# PIC32MX330F064L register map
Vendor: Microchip
Registers are 32-bit, read-write, reset 0x0 unless marked. A register's access mark holds for its fields unless they carry their own. Addresses are absolute, and some are shared; only a register's first bit layout is shown; [hi:lo] are bit positions; {n}, {i} and the like mark numbered series.

## ADC10
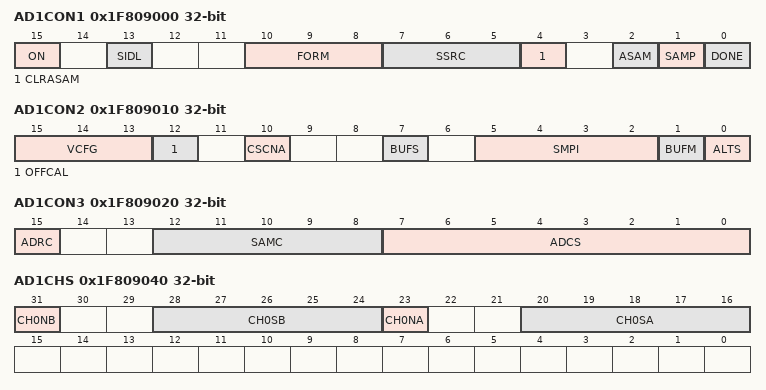
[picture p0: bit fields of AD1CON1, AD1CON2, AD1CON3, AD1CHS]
0x1F809000 AD1CON1
  [15] ON
  [13] SIDL
  [10:8] FORM
  [7:5] SSRC
  [4] CLRASAM
  [2] ASAM
  [1] SAMP
  [0] DONE — (can only be cleared)
0x1F809010 AD1CON2
  [15:13] VCFG, [12] OFFCAL, [10] CSCNA, [7] BUFS ro, [5:2] SMPI, [1] BUFM, [0] ALTS
0x1F809020 AD1CON3
  [15] ADRC, [12:8] SAMC, [7:0] ADCS
0x1F809040 AD1CHS
  [31] CH0NB, [28:24] CH0SB, [23] CH0NA, [20:16] CH0SA
0x1F809050 AD1CSSL
  [30:0] CSSL
{0x1F809070+0x10*i} ADC1BUF{i} ro (i=0..9)
0x1F809110 ADC1BUFA ro
0x1F809120 ADC1BUFB ro
0x1F809130 ADC1BUFC ro
0x1F809140 ADC1BUFD ro
0x1F809150 ADC1BUFE ro
0x1F809160 ADC1BUFF ro

## CVR
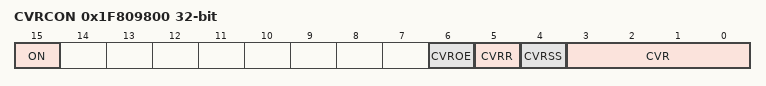
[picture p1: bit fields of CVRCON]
0x1F809800 CVRCON
  [15] ON, [6] CVROE, [5] CVRR, [4] CVRSS, [3:0] CVR

## CMP1
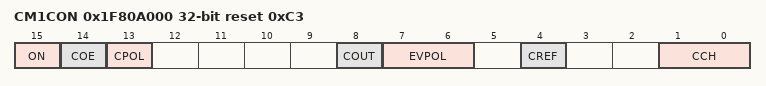
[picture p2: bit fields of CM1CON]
0x1F80A000 CM1CON reset 0xC3
  [15] ON, [14] COE, [13] CPOL, [8] COUT, [7:6] EVPOL, [4] CREF, [1:0] CCH

## CMP2
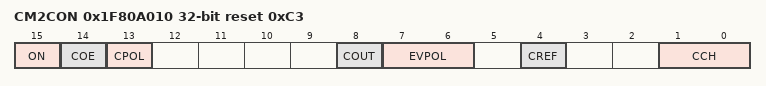
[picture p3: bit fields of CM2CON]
0x1F80A010 CM2CON reset 0xC3
  [15] ON, [14] COE, [13] CPOL, [8] COUT, [7:6] EVPOL, [4] CREF, [1:0] CCH

## cmp_control_pb
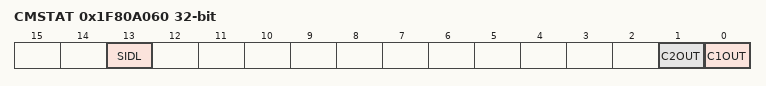
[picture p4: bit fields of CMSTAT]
0x1F80A060 CMSTAT
  [13] SIDL, [1] C2OUT ro, [0] C1OUT ro

## CTMU
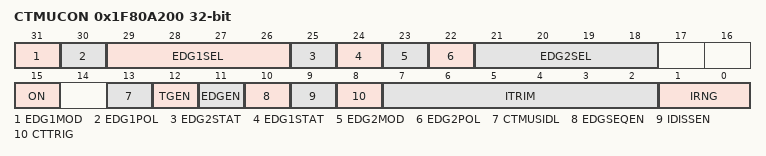
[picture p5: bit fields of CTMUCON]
0x1F80A200 CTMUCON
  [31] EDG1MOD, [30] EDG1POL, [29:26] EDG1SEL, [25] EDG2STAT, [24] EDG1STAT, [23] EDG2MOD, [22] EDG2POL, [21:18] EDG2SEL, [15] ON, [13] CTMUSIDL, [12] TGEN, [11] EDGEN, [10] EDGSEQEN, [9] IDISSEN, [8] CTTRIG, [7:2] ITRIM, [1:0] IRNG

## INT
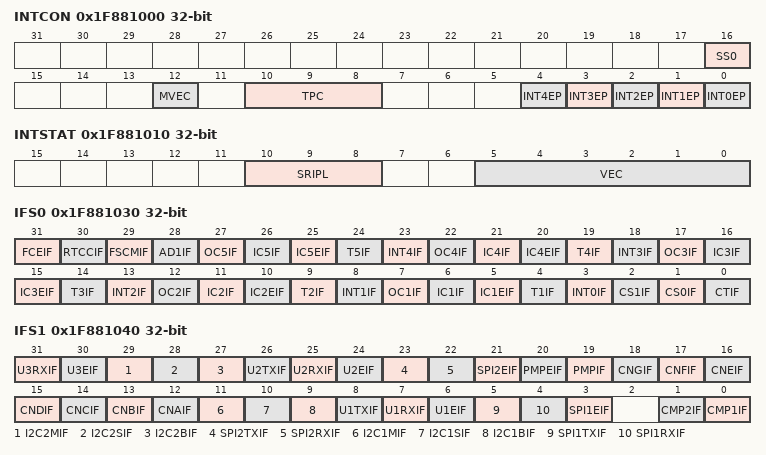
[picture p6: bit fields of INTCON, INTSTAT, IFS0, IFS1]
0x1F881000 INTCON
  [16] SS0, [12] MVEC, [10:8] TPC, [n] INT{n}EP (n=0..4)
0x1F881010 INTSTAT
  [10:8] SRIPL, [5:0] VEC
0x1F881020 IPTMR
0x1F881030 IFS0 reset not defined — (power-on value 00000x0000x0000x0000000000000000)
  [31] FCEIF, [30] RTCCIF, [29] FSCMIF, [28] AD1IF, [5n+2] OC{n}IF (n=1..5), [5n+1] IC{n}IF (n=1..5), [5n] IC{n}EIF (n=1..5), [5n-1] T{n}IF (n=1..5), [5n+3] INT{n}IF (n=0..4), [2] CS1IF, [1] CS0IF, [0] CTIF
0x1F881040 IFS1 reset not defined — (power-on value xxxxxx00xxxx00000000000000000-00)
  [31] U3RXIF, [30] U3EIF, [29] I2C2MIF, [28] I2C2SIF, [27] I2C2BIF, [26] U2TXIF, [25] U2RXIF, [24] U2EIF, [23] SPI2TXIF, [22] SPI2RXIF, [21] SPI2EIF, [20] PMPEIF, [19] PMPIF, [18] CNGIF, [17] CNFIF, [16] CNEIF, [15] CNDIF, [14] CNCIF, [13] CNBIF, [12] CNAIF, [11] I2C1MIF, [10] I2C1SIF, [9] I2C1BIF, [8] U1TXIF, [7] U1RXIF, [6] U1EIF, [5] SPI1TXIF, [4] SPI1RXIF, [3] SPI1EIF, [1] CMP2IF, [0] CMP1IF
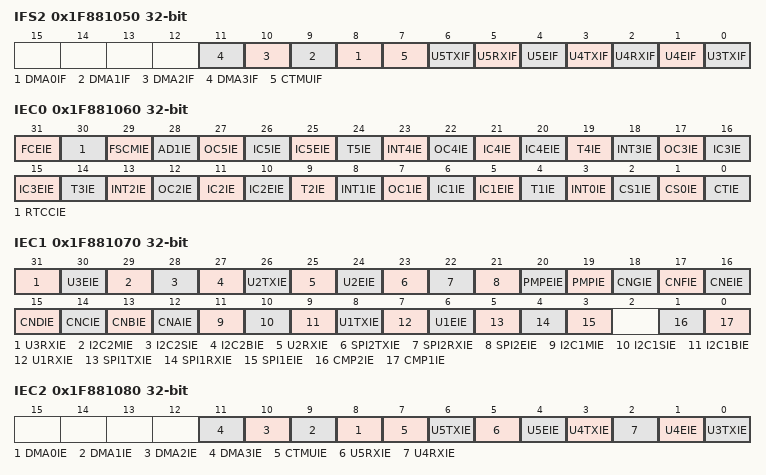
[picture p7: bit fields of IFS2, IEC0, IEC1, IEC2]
0x1F881050 IFS2 reset not defined — (power-on value x-------------------xxxxxxxxxxxx)
  [n+8] DMA{n}IF (n=0..3), [7] CTMUIF, [6] U5TXIF, [5] U5RXIF, [4] U5EIF, [3] U4TXIF, [2] U4RXIF, [1] U4EIF, [0] U3TXIF
0x1F881060 IEC0 reset not defined — (power-on value 00000x0000x0000x0000000000000000)
  [31] FCEIE, [30] RTCCIE, [29] FSCMIE, [28] AD1IE, [5n+2] OC{n}IE (n=1..5), [5n+1] IC{n}IE (n=1..5), [5n] IC{n}EIE (n=1..5), [5n-1] T{n}IE (n=1..5), [5n+3] INT{n}IE (n=0..4), [2] CS1IE, [1] CS0IE, [0] CTIE
0x1F881070 IEC1 reset not defined — (power-on value xxxxxx-0xxxx-0000000000000000-00)
  [31] U3RXIE, [30] U3EIE, [29] I2C2MIE, [28] I2C2SIE, [27] I2C2BIE, [26] U2TXIE, [25] U2RXIE, [24] U2EIE, [23] SPI2TXIE, [22] SPI2RXIE, [21] SPI2EIE, [20] PMPEIE, [19] PMPIE, [18] CNGIE, [17] CNFIE, [16] CNEIE, [15] CNDIE, [14] CNCIE, [13] CNBIE, [12] CNAIE, [11] I2C1MIE, [10] I2C1SIE, [9] I2C1BIE, [8] U1TXIE, [7] U1RXIE, [6] U1EIE, [5] SPI1TXIE, [4] SPI1RXIE, [3] SPI1EIE, [1] CMP2IE, [0] CMP1IE
0x1F881080 IEC2 reset not defined — (power-on value --------------------xxxxxxxxxxxx)
  [n+8] DMA{n}IE (n=0..3), [7] CTMUIE, [6] U5TXIE, [5] U5RXIE, [4] U5EIE, [3] U4TXIE, [2] U4RXIE, [1] U4EIE, [0] U3TXIE
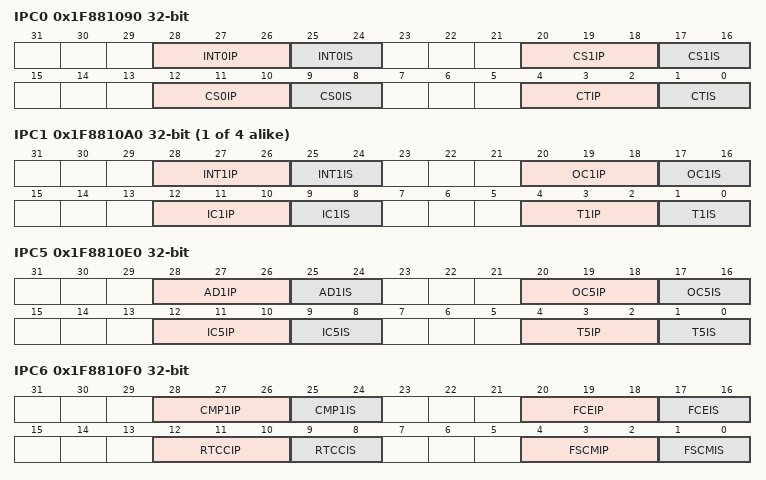
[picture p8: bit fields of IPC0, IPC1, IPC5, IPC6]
0x1F881090 IPC0
  [28:26] INT0IP, [25:24] INT0IS, [20:18] CS1IP, [17:16] CS1IS, [12:10] CS0IP, [9:8] CS0IS, [4:2] CTIP, [1:0] CTIS
{0x1F881090+0x10*i} IPC{i} (i=1..4)
  [28:26] INT{i}IP, [25:24] INT{i}IS, [20:18] OC{i}IP, [17:16] OC{i}IS, [12:10] IC{i}IP, [9:8] IC{i}IS, [4:2] T{i}IP, [1:0] T{i}IS
0x1F8810E0 IPC5
  [28:26] AD1IP, [25:24] AD1IS, [20:18] OC5IP, [17:16] OC5IS, [12:10] IC5IP, [9:8] IC5IS, [4:2] T5IP, [1:0] T5IS
0x1F8810F0 IPC6
  [28:26] CMP1IP, [25:24] CMP1IS, [20:18] FCEIP, [17:16] FCEIS, [12:10] RTCCIP, [9:8] RTCCIS, [4:2] FSCMIP, [1:0] FSCMIS
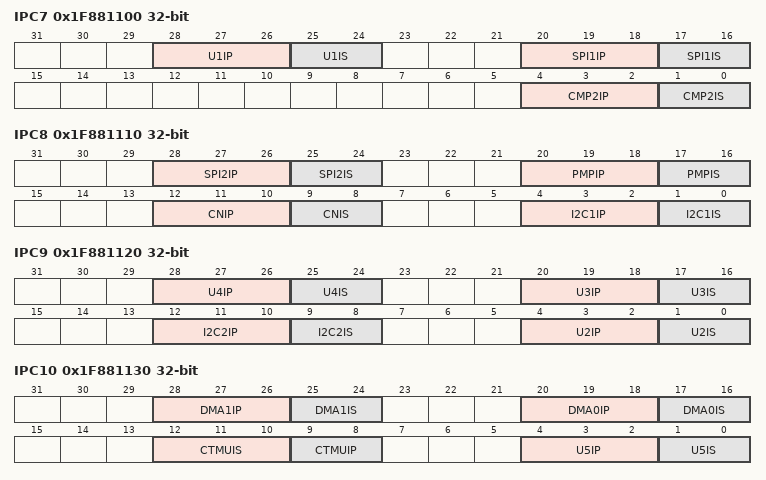
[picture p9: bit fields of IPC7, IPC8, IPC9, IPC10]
0x1F881100 IPC7
  [28:26] U1IP, [25:24] U1IS, [20:18] SPI1IP, [17:16] SPI1IS, [4:2] CMP2IP, [1:0] CMP2IS
0x1F881110 IPC8
  [28:26] SPI2IP, [25:24] SPI2IS, [20:18] PMPIP, [17:16] PMPIS, [12:10] CNIP, [9:8] CNIS, [4:2] I2C1IP, [1:0] I2C1IS
0x1F881120 IPC9
  [28:26] U4IP, [25:24] U4IS, [20:18] U3IP, [17:16] U3IS, [12:10] I2C2IP, [9:8] I2C2IS, [4:2] U2IP, [1:0] U2IS
0x1F881130 IPC10 reset not defined — (power-on value ---xxxxx---xxxxx---xxxxx---xxxxx)
  [28:26] DMA1IP, [25:24] DMA1IS, [20:18] DMA0IP, [17:16] DMA0IS, [12:10] CTMUIS, [9:8] CTMUIP, [4:2] U5IP, [1:0] U5IS
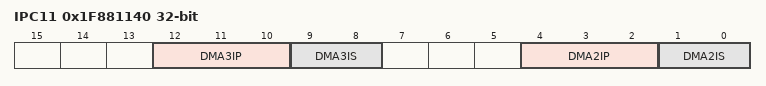
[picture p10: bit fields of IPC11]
0x1F881140 IPC11 reset not defined — (power-on value -------------------xxxxx---xxxxx)
  [12:10] DMA3IP, [9:8] DMA3IS, [4:2] DMA2IP, [1:0] DMA2IS
